# BlueNRG1 register map
Vendor: STMicroelectronics; Series: BlueNRG1; File version: 2.0.0
CPU: CM0 r0p0, little endian, no MPU, no FPU, 2 interrupt priority bits
Registers are 32-bit, read-write, reset 0x0 unless marked. A register's access mark holds for its fields unless they carry their own. Offsets are from the block's base; [hi:lo] are bit positions; {n}, {i} and the like mark numbered series.

## CKGEN_SOC — Clock Gen SOC
Base 0x40900000
0x00 CONTROL reset 0x1FA03F0 — Control clock and reset of SOC
  [13:10] UART_CKDIV — UART baud rate clock setting from 1 to 16 MHz according to the formula 16 / (n + 1) MHz.
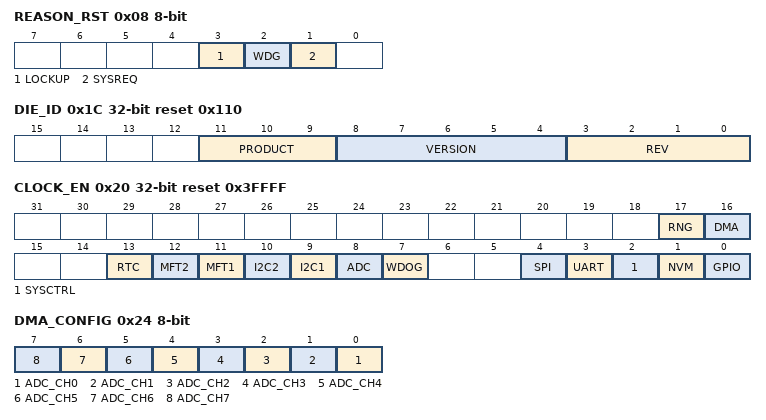
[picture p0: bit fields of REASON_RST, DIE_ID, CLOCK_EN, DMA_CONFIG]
0x08 REASON_RST 8-bit ro — Indicates the reset reason from Cortex-M0
  [3] LOCKUP — Reset caused by Cortex-M0 asserting LOCKUP signal
  [2] WDG — Reset caused by assertion of watchdog reset
  [1] SYSREQ — Reset caused by Cortex-M0 debug asserting SYSRESETREQ
0x1C DIE_ID ro reset 0x110 — Identification information of the device
  [11:9] PRODUCT
  [8:4] VERSION — Cut version
  [3:0] REV — Cut revision
0x20 CLOCK_EN reset 0x3FFFF — Enable or gates the APB clock of the peripherals
  [17] RNG — RNG AHB clock
  [16] DMA — DMA AHB clock
  [13] RTC — RTC clock
  [12] MFT2 — MFT2 clock
  [11] MFT1 — MFT1 clock
  [10] I2C2 — I2C2 clock
  [9] I2C1 — I2C1 clock
  [8] ADC — ADC clock
  [7] WDOG — Watchdog clock
  [4] SPI — SPI clock
  [3] UART — UART clock
  [2] SYSCTRL — System controller clock
  [1] NVM — Flash controller clock
  [0] GPIO — GPIO clock
0x24 DMA_CONFIG 8-bit
  [all] fields
    1=enable; 0=disable
  [n] ADC_CH{n} (n=0..7) — Select ADC on DMA channel {n} instead of peripheral

## AHBUPCONV — AHB up/down converter converter
Base 0x40C00000
0x00 COMMAND 8-bit — AHB up/down converter command register

## BLUE_CTRL — BLUE Controller
Base 0x48000000
0x04 TIMEOUT — Timeout programming register
0x0C RADIO_CONFIG — Radio configuration register

## CKGEN_BLE — Clock Gen BLE
Base 0x48100000
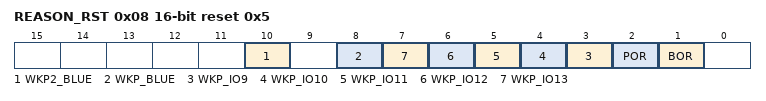
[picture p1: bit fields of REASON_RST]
0x08 REASON_RST 16-bit ro reset 0x5 — Indicates the reset reason from BLE
  [10] WKP2_BLUE — Wakeup coms from the timer 2 expiration in the wakeup control block of the BLE radio
  [8] WKP_BLUE — Wakeup coms from the timer 1 expiration in the wakeup control block of the BLE radio
  [n-6] WKP_IO{n} (n=9..13) — Wakeup from external IO{n}
  [2] POR — Reset from POR
  [1] BOR — Reset from BOR
0x0C CLK32K_COUNT 16-bit reset 0xF — Counter of 32 kHz clock
  [8:0] SLOW_COUNT — Program the window length (in slow clock period unit) for slow clock measurement
0x10 CLK32K_PERIOD — Period of 32 kHz clock
  [18:0] SLOW_PERIOD ro — Indicates slow clock period information. The result provided in this field corresponds to the length of SLOW_COUNT periods of the slow clock (32 kHz) measured in 16 MHz half-period unit. The measurement is done automatically each time the device enters in active2 mode using SLOW_COUNT = 16. A new calculation can be launched by writing zero in CLK32K_PERIOD register. In this case, the time window uses the value programmed in SLOW_COUNT field.
0x14 CLK32K_FREQ ro — Measurement of frequency of 32 kHz clock
  [26:0] SLOW_FREQ — Value equal to 2^33 / SLOW_PERIOD
0x18 CLK32K_IT 16-bit — Interrupt event for 32 kHz clock measurement
  [0] CLK32K_MEAS_IRQ — When read, provides the status of the interrupt indicating slow lock measurement is finished:<ul><li>0: No pending interrupt.</li><li>1: Pending interrupt.</li></ul>When written, clears the interrupt:<ul><li>0: No effect.</li><li>1: Clear the interrupt.</li></ul>

## DMA
Base 0xA0000000
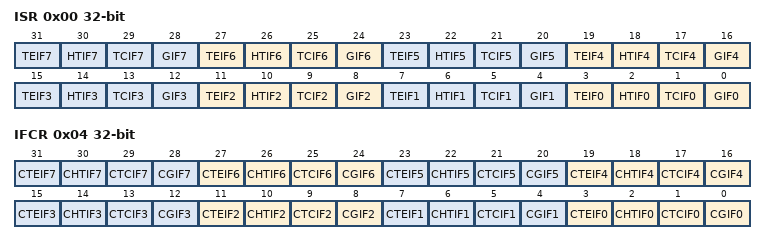
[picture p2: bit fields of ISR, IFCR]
0x00 ISR ro — DMA interrupt status register
  [4n+3] TEIF{n} (n=0..7) — Channel {n} transfer error flag. This bit is set by hardware. It is cleared by software writing 1 to the corresponding bit in the IFCR register.<ul><li>0: No transfer error (TE) event on channel {n}.</li><li>1: A transfer error (TE) occurred on channel {n}.</li></ul>
  [4n+2] HTIF{n} (n=0..7) — Channel {n} half transfer flag. This bit is set by hardware. It is cleared by software writing 1 to the corresponding bit in the IFCR register.<ul><li>0: No half transfer (HT) event on channel {n}.</li><li>1: A half transfer (HT) event occurred on channel {n}.</li></ul>
  [4n+1] TCIF{n} (n=0..7) — Channel {n} transfer complete flag. This bit is set by hardware. It is cleared by software writing 1 to the corresponding bit in the IFCR register.<ul><li>0: No transfer complete (TC) on channel {n}.</li><li>1: A transfer complete (TC) occurred on channel {n}.</li></ul>
  [4n] GIF{n} (n=0..7) — Channel {n} global interrupt flag. This bit is set by hardware. It is cleared by software writing 1 to the corresponding bit in the IFCR register.<ul><li>0: No TE, HT or TC event on channel {n}.</li><li>1: A TE, HT or TC event occurred on channel {n}.</li></ul>
0x04 IFCR wo — DMA interrupt flag clear register
  [4n+3] CTEIF{n} (n=0..7) — Channel {n} transfer error flag. This bit is set by software.<ul><li>0: No effect.</li><li>1: Clears the corresponding TEIF flag in the ISR register.</li></ul>
  [4n+2] CHTIF{n} (n=0..7) — Channel {n} half transfer flag. This bit is set by software.<ul><li>0: No effect.</li><li>1: Clears the corresponding HTIF flag in the ISR register.</li></ul>
  [4n+1] CTCIF{n} (n=0..7) — Channel {n} transfer complete flag. This bit is set by software.<ul><li>0: No effect.</li><li>1: Clears the corresponding TCIF flag in the ISR register.</li></ul>
  [4n] CGIF{n} (n=0..7) — Channel {n} global interrupt flag. This bit is set by software.<ul><li>0: No effect.</li><li>1: Clears the GIF, TEIF, HTIF and TCIF flags in the ISR register.</li></ul>

## RNG
Base 0xB0000000
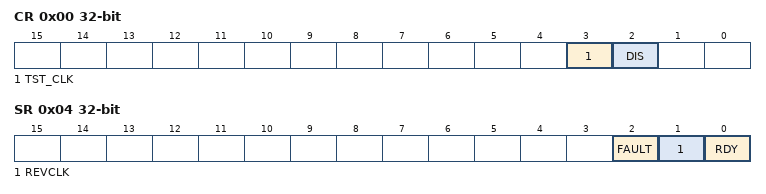
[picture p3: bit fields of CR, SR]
0x00 CR — RNG configuration register
  [3] TST_CLK — RNG test clock bit. Writing this bit with 1b starts the logic that detects the presence of the CLK. Then wait (with a timeout of at least four RNGCLK cycles) for REVCLK = 1b in SR register. If REVCLK = 0b after timeout elapsed, it means that RNGCLK is not present and reading VAL register will trigger an AHB error response. For security reason, software should check before reading random values that the RNGCLK is present.
  [2] DIS — Set the state of the random number generator.<ul><li>0: RNG is enable.</li><li>1: RNG is disabled. The internal free-running oscillators are put in power-down mode and the RNG clock is stopped at the input of the block.</li></ul>
0x04 SR ro — RNG status register
  [2] FAULT rw — Fault reveal bit. This bit is set by hardware when a faulty sequence of bits occurs. The faulty sequences are:<ul><li>0: Sequence of more than 32 consecutive bits of same value (0b or 1b).</li><li>1: Sequence of more than 16 consecutive alternation of 0b and 1b (010101...01b).</li></ul>Writing this bit:<ul><li>0: No effect.</li><li>1: Clear the bit.</li></ul>
  [1] REVCLK rw — REVCLK clock reveal bit. A write with 1b to bit TSTCLK in CR resets this bit. If the RNGCLK is present, this bit will be 1b after four RNGCLK cycles after the end of the write to RNG_CR.If REVCLK = 0b after this period, it means the RNGCLK is not present and reading VAL will trigger a AHB error response.
  [0] RDY — New random value ready.<ul><li>0: The RNG_VAL register value is not yet valid. If performing a read access to VAL, the host will be put on hold (by wait-states insertion on the AHB bus) until a random value is available.</li><li>1: The VAL register contains a valid random number.</li></ul>This bit remains at 0 when the RNG is disabled (RNGDIS bit = 1b in CR)
0x08 VAL ro (reset mask 0xFFFF) — RNG 16 bit random value
